# GD32F5HC register map
File version: 1.0
CPU: CM33 r0p4, little endian, MPU, FPU, 4 interrupt priority bits
Registers are 32-bit, read-write, reset 0x0 unless marked. A register's access mark holds for its fields unless they carry their own. Offsets are from the block's base; [hi:lo] are bit positions; {n}, {i} and the like mark numbered series.

## PKCAU — Public Key Cryptographic Acceleration Unit
Base 0x4C061000
Same registers: SEC_PKCAU 0x5C061000
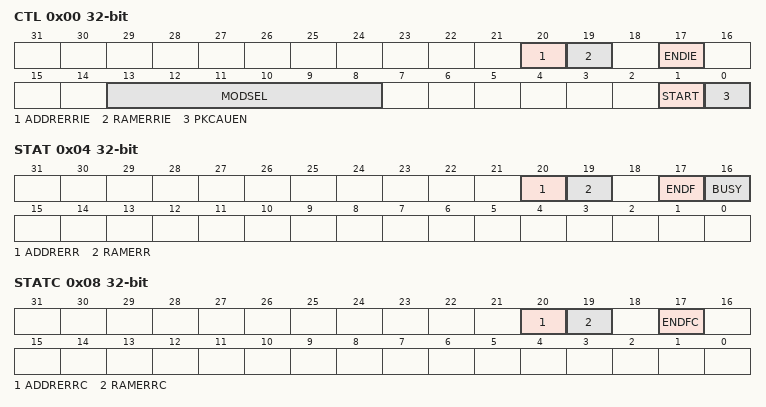
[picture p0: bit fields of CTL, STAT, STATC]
0x00 CTL — Control register
  [20] ADDRERRIE — Address error interrupt enable
  [19] RAMERRIE — RAM error interrupt enable
  [17] ENDIE — End of operation interrupt enable
  [13:8] MODSEL — PKCAU operation mode selection
  [1] START — PKCAU starts operation
  [0] PKCAUEN — PKCAU enable
0x04 STAT ro — Status register
  [20] ADDRERR — Address error
  [19] RAMERR — PKCAU RAM error
  [17] ENDF — End of PKCAU operation
  [16] BUSY — Busy flag
0x08 STATC wo — Status clear register
  [20] ADDRERRC — Address error flag clear
  [19] RAMERRC — PKCAU RAM error flag clear
  [17] ENDFC — End of PKCAU operation flag clear

## PMU — Power management unit
Base 0x40007000
Same registers: SEC_PMU 0x50007000
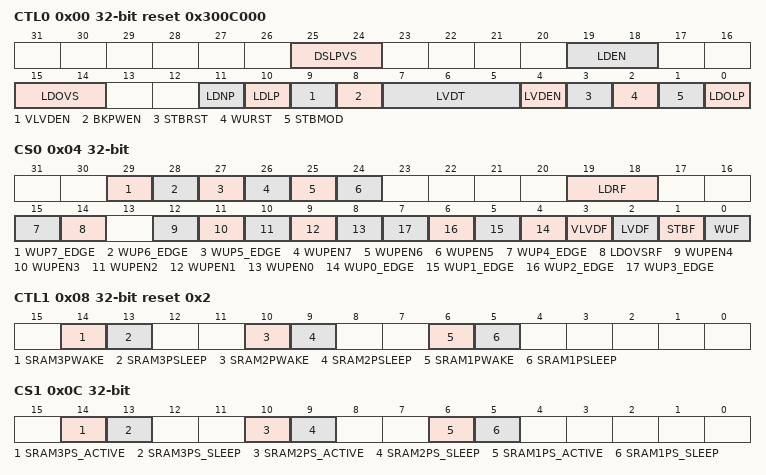
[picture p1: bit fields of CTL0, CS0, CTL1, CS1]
0x00 CTL0 reset 0x300C000 — Control register 0
  [25:24] DSLPVS — Deep-sleep mode voltage select
  [19:18] LDEN — Low-driver mode enable in Deep-sleep mode
  [15:14] LDOVS — LDO output voltage select
  [11] LDNP — Low-driver mode when use normal power LDO
  [10] LDLP — Low-driver mode when use low power LDO.
  [9] VLVDEN — VDDA low voltage detect enable
  [8] BKPWEN — Backup Domain Write Enable
  [7:5] LVDT — Low Voltage Detector Threshold
  [4] LVDEN — Low Voltage Detector Enable
  [3] STBRST — Standby Flag Reset
  [2] WURST — Wakeup Flag Reset
  [1] STBMOD — Standby Mode
  [0] LDOLP — LDO Low Power Mode
0x04 CS0 access per field — Control and status register 0
  [29] WUP7_EDGE rw — WKUP Pin7 edge selection
  [28] WUP6_EDGE rw — WKUP Pin6 edge selection
  [27] WUP5_EDGE rw — WKUP Pin5 edge selection
  [26] WUPEN7 rw — WKUP Pin7 (PD3) Enable
  [25] WUPEN6 rw — WKUP Pin6 (PB0) Enable
  [24] WUPEN5 rw — WKUP Pin5 (PD4) Enable
  [19:18] LDRF rw — Low-driver mode ready flag
  [15] WUP4_EDGE rw — WKUP Pin4 edge selection
  [14] LDOVSRF ro — LDO voltage select ready flag
  [12] WUPEN4 rw — WKUP Pin4 (PD5) Enable
  [11] WUPEN3 rw — WKUP Pin3 (PA12) Enable
  [10] WUPEN2 rw — WKUP Pin2 (PB2) Enable
  [9] WUPEN1 rw — WKUP Pin1 (PA15) Enable
  [8] WUPEN0 rw — WKUP Pin0 (PA2) Enable
  [n+4] WUP{n}_EDGE rw (n=0..3) — WKUP Pin{n} edge selection
  [3] VLVDF ro — VDDA Low Voltage Detector Status Flag
  [2] LVDF ro — Low Voltage Detector Status Flag
  [1] STBF ro — Standby Flag
  [0] WUF ro — Wakeup Flag
0x08 CTL1 reset 0x2 — Control register 1
  [14] SRAM3PWAKE — Setting this bit by software will wakeup SRAM3.
  [13] SRAM3PSLEEP — SRAM3 go to sleep when setting this bit by software.
  [10] SRAM2PWAKE — Setting this bit by software will wakeup SRAM2.
  [9] SRAM2PSLEEP — SRAM2 go to sleep when setting this bit by software.
  [6] SRAM1PWAKE — Setting this bit by software will wakeup SRAM1.
  [5] SRAM1PSLEEP — SRAM1 go to sleep when setting this bit by software.
0x0C CS1 ro — Control and status register 1
  [14] SRAM3PS_ACTIVE — SRAM3 is in active state when this bit is set.
  [13] SRAM3PS_SLEEP — SRAM3 is in sleep state when this bit is set.
  [10] SRAM2PS_ACTIVE — SRAM2 is in active state when this bit is set.
  [9] SRAM2PS_SLEEP — SRAM2 is in sleep state when this bit is set.
  [6] SRAM1PS_ACTIVE — SRAM1 is in active state when this bit is set.
  [5] SRAM1PS_SLEEP — SRAM1 is in sleep state when this bit is set.
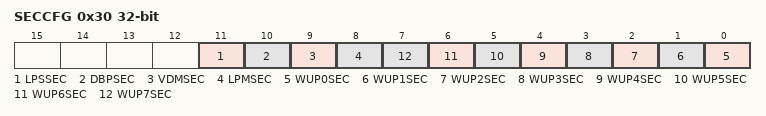
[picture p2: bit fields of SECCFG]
0x30 SECCFG — Secure configuration register
  [11] LPSSEC — SRAM_sleep mode security
  [10] DBPSEC — Backup Domain write access security
  [9] VDMSEC — Voltage detection and monitoring security
  [8] LPMSEC — Low-power mode security
  [n] WUP{n}SEC (n=0..7) — WKUP pin {n} security
0x34 PRICFG — Privilege configuration register
  [0] PRIV — This bit can be read by both privileged and unprivileged access.
0x104 DSLVC_ULKKEY wo — Deepsleep voltage configure unlock register
  [31:0] KEY — The DSLPVS bit field in PMU_CTL0 register.
